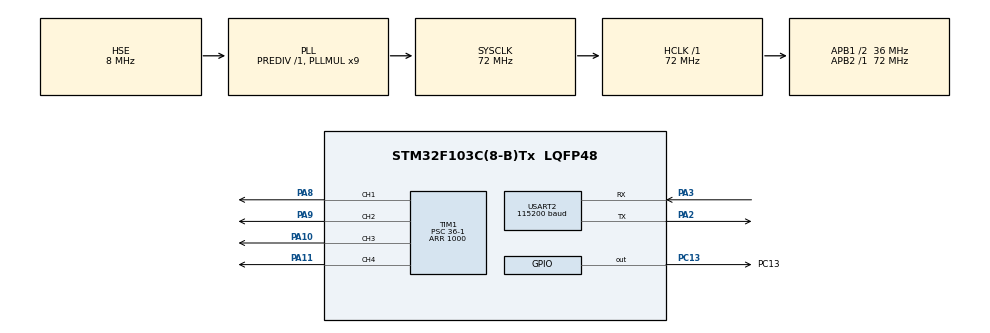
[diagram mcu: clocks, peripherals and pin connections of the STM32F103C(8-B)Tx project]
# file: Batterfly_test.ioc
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Dma.Request0=USART2_RX
Dma.USART2_RX.0.Direction=DMA_PERIPH_TO_MEMORY
Dma.USART2_RX.0.Instance=DMA1_Channel6
Dma.USART2_RX.0.MemDataAlignment=DMA_MDATAALIGN_BYTE
Dma.USART2_RX.0.MemInc=DMA_MINC_ENABLE
Dma.USART2_RX.0.Mode=DMA_NORMAL
Dma.USART2_RX.0.PeriphDataAlignment=DMA_PDATAALIGN_BYTE
Dma.USART2_RX.0.PeriphInc=DMA_PINC_DISABLE
Dma.USART2_RX.0.Priority=DMA_PRIORITY_LOW
FREERTOS.Tasks01=defaultTask,24,128,StartDefaultTask,Default,NULL,Dynamic,NULL,NULL
Mcu.Family=STM32F1
Mcu.Name=STM32F103C(8-B)Tx
Mcu.Package=LQFP48
NVIC.DMA1_Channel6_IRQn=true\:5\:0\:false\:false\:true\:true\:false\:true\:true
NVIC.PriorityGroup=NVIC_PRIORITYGROUP_4
NVIC.TIM4_IRQn=true\:15\:0\:false\:false\:true\:false\:false\:true\:true
NVIC.TimeBase=TIM4_IRQn
NVIC.TimeBaseIP=TIM4
NVIC.USART2_IRQn=true\:5\:0\:false\:false\:true\:true\:true\:true\:true
PA10.Signal=S_TIM1_CH3
PA11.Signal=S_TIM1_CH4
PA13.Mode=Serial_Wire
PA13.Signal=SYS_JTMS-SWDIO
PA14.Mode=Serial_Wire
PA14.Signal=SYS_JTCK-SWCLK
PA2.Mode=Asynchronous
PA2.Signal=USART2_TX
PA3.Mode=Asynchronous
PA3.Signal=USART2_RX
PA8.Signal=S_TIM1_CH1
PA9.Signal=S_TIM1_CH2
PC13-TAMPER-RTC.GPIO_Label=PC13
PC13-TAMPER-RTC.Signal=GPIO_Output
PD0-OSC_IN.Mode=HSE-External-Oscillator
PD0-OSC_IN.Signal=RCC_OSC_IN
PD1-OSC_OUT.Mode=HSE-External-Oscillator
PD1-OSC_OUT.Signal=RCC_OSC_OUT
ProjectManager.HeapSize=0x200
ProjectManager.StackSize=0x400
ProjectManager.TargetToolchain=Makefile
RCC.ADCPresc=RCC_ADCPCLK2_DIV6
RCC.AHBFreq_Value=72000000
RCC.APB1CLKDivider=RCC_HCLK_DIV2
RCC.APB1Freq_Value=36000000
RCC.APB1TimFreq_Value=72000000
RCC.APB2Freq_Value=72000000
RCC.APB2TimFreq_Value=72000000
RCC.HCLKFreq_Value=72000000
RCC.PLLMUL=RCC_PLL_MUL9
RCC.PLLSourceVirtual=RCC_PLLSOURCE_HSE
RCC.SYSCLKFreq_VALUE=72000000
RCC.SYSCLKSource=RCC_SYSCLKSOURCE_PLLCLK
RCC.USBFreq_Value=72000000
SH.S_TIM1_CH1.0=TIM1_CH1,PWM Generation1 CH1
SH.S_TIM1_CH2.0=TIM1_CH2,PWM Generation2 CH2
SH.S_TIM1_CH3.0=TIM1_CH3,PWM Generation3 CH3
SH.S_TIM1_CH4.0=TIM1_CH4,PWM Generation4 CH4
STMicroelectronics.X-CUBE-ALGOBUILD.1.4.0.LibraryCcDSPOoLibraryJjDSPOoLibrary=true
TIM1.Channel-PWM\ Generation1\ CH1=TIM_CHANNEL_1
TIM1.Channel-PWM\ Generation2\ CH2=TIM_CHANNEL_2
TIM1.Channel-PWM\ Generation3\ CH3=TIM_CHANNEL_3
TIM1.Channel-PWM\ Generation4\ CH4=TIM_CHANNEL_4
TIM1.Period=1000
TIM1.Prescaler=36-1
USART2.BaudRate=115200
USART2.Parity=PARITY_NONE
USART2.VirtualMode=VM_ASYNC
USART2.WordLength=WORDLENGTH_8B
VP_FREERTOS_VS_CMSIS_V2.Mode=CMSIS_V2
VP_STMicroelectronics.X-CUBE-ALGOBUILD_VS_DSPOoLibraryJjLibrary_1.4.0_1.4.0.Mode=DSPOoLibraryJjLibrary
VP_SYS_VS_tim4.Mode=TIM4
board=custom

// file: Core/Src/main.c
/* USER CODE BEGIN Header */
/**
  ******************************************************************************
  * @file           : main.c
  * @brief          : Main program body
  ******************************************************************************
  * @attention
  *
  * Copyright (c) 2025 STMicroelectronics.
  * All rights reserved.
  *
  * This software is licensed under terms that can be found in the LICENSE file
  * in the root directory of this software component.
  * If no LICENSE file comes with this software, it is provided AS-IS.
  *
  ******************************************************************************
  */
/* USER CODE END Header */
#include "main.h"
#include "cmsis_os.h"
#include "dma.h"
#include "tim.h"
#include "usart.h"
#include "gpio.h"

/* USER CODE BEGIN Includes */
#include "butterfly.h"
/* USER CODE END Includes */

void SystemClock_Config(void);
void MX_FREERTOS_Init(void);

int main(void)
{

  /* MCU Configuration--------------------------------------------------------*/

  /* Reset of all peripherals, Initializes the Flash interface and the Systick. */
  HAL_Init();

  /* Configure the system clock */
  SystemClock_Config();

  /* Initialize all configured peripherals */
  MX_GPIO_Init();
  MX_DMA_Init();
  MX_USART2_UART_Init();
  MX_TIM1_Init();
  /* USER CODE BEGIN 2 */
  Butterfly_Init();

  /* USER CODE END 2 */

  /* Init scheduler */
  osKernelInitialize();  /* Call init function for freertos objects (in cmsis_os2.c) */
  MX_FREERTOS_Init();

  /* Start scheduler */
  osKernelStart();

  /* We should never get here as control is now taken by the scheduler */

  /* Infinite loop */
  while (1)
  {

  }
}

void SystemClock_Config(void)
{
  RCC_OscInitTypeDef RCC_OscInitStruct = {0};
  RCC_ClkInitTypeDef RCC_ClkInitStruct = {0};

  /** Initializes the RCC Oscillators according to the specified parameters
  * in the RCC_OscInitTypeDef structure.
  */
  RCC_OscInitStruct.OscillatorType = RCC_OSCILLATORTYPE_HSE;
  RCC_OscInitStruct.HSEState = RCC_HSE_ON;
  RCC_OscInitStruct.HSEPredivValue = RCC_HSE_PREDIV_DIV1;
  RCC_OscInitStruct.HSIState = RCC_HSI_ON;
  RCC_OscInitStruct.PLL.PLLState = RCC_PLL_ON;
  RCC_OscInitStruct.PLL.PLLSource = RCC_PLLSOURCE_HSE;
  RCC_OscInitStruct.PLL.PLLMUL = RCC_PLL_MUL9;
  if (HAL_RCC_OscConfig(&RCC_OscInitStruct) != HAL_OK)
  {
    Error_Handler();
  }

  /** Initializes the CPU, AHB and APB buses clocks
  */
  RCC_ClkInitStruct.ClockType = RCC_CLOCKTYPE_HCLK|RCC_CLOCKTYPE_SYSCLK
                              |RCC_CLOCKTYPE_PCLK1|RCC_CLOCKTYPE_PCLK2;
  RCC_ClkInitStruct.SYSCLKSource = RCC_SYSCLKSOURCE_PLLCLK;
  RCC_ClkInitStruct.AHBCLKDivider = RCC_SYSCLK_DIV1;
  RCC_ClkInitStruct.APB1CLKDivider = RCC_HCLK_DIV2;
  RCC_ClkInitStruct.APB2CLKDivider = RCC_HCLK_DIV1;

  if (HAL_RCC_ClockConfig(&RCC_ClkInitStruct, FLASH_LATENCY_2) != HAL_OK)
  {
    Error_Handler();
  }
}

void HAL_TIM_PeriodElapsedCallback(TIM_HandleTypeDef *htim)
{
  if (htim->Instance == TIM4)
  {
    HAL_IncTick();
  }
}

void Error_Handler(void)
{
  __disable_irq();
  while (1)
  {
  }
}

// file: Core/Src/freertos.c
/* USER CODE BEGIN Header */
/**
  ******************************************************************************
  * File Name          : freertos.c
  * Description        : Code for freertos applications
  ******************************************************************************
  * @attention
  *
  * Copyright (c) 2025 STMicroelectronics.
  * All rights reserved.
  *
  * This software is licensed under terms that can be found in the LICENSE file
  * in the root directory of this software component.
  * If no LICENSE file comes with this software, it is provided AS-IS.
  *
  ******************************************************************************
  */
/* USER CODE END Header */

#include "FreeRTOS.h"
#include "task.h"
#include "main.h"
#include "cmsis_os.h"

/* Definitions for defaultTask */
osThreadId_t defaultTaskHandle;
const osThreadAttr_t defaultTask_attributes = {
  .name = "defaultTask",
  .stack_size = 128 * 2,
  .priority = (osPriority_t) osPriorityNormal,
};

void StartDefaultTask(void *argument);

void MX_FREERTOS_Init(void); /* (MISRA C 2004 rule 8.1) */

void MX_FREERTOS_Init(void) {

  /* Create the thread(s) */
  /* creation of defaultTask */
  defaultTaskHandle = osThreadNew(StartDefaultTask, NULL, &defaultTask_attributes);

}

void StartDefaultTask(void *argument)
{
  /* USER CODE BEGIN StartDefaultTask */
  /* Infinite loop */
  for(;;)
  {
    HAL_GPIO_TogglePin(PC13_GPIO_Port, PC13_Pin);
    osDelay(1000);
  }
  /* USER CODE END StartDefaultTask */
}
